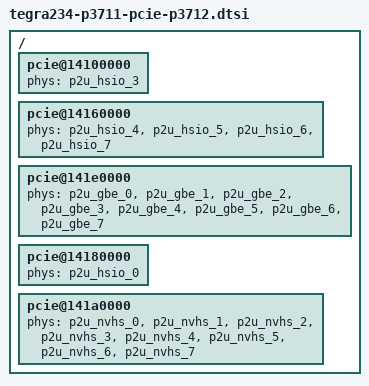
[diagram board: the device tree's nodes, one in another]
/*
 * Copyright (c) 2021, NVIDIA CORPORATION.  All rights reserved.
 *
 * This program is free software; you can redistribute it and/or modify
 * it under the terms of the GNU General Public License as published by
 * the Free Software Foundation; version 2 of the License.
 *
 * This program is distributed in the hope that it will be useful, but WITHOUT
 * ANY WARRANTY; without even the implied warranty of MERCHANTABILITY or
 * FITNESS FOR A PARTICULAR PURPOSE.  See the GNU General Public License for
 * more details.
 */


/ {
	/* C1 - M.2 Key-E */
	pcie@14100000 {
		status = "okay";

		phys = <&p2u_hsio_3>;
		phy-names = "p2u-0";
	};

	/* C4 - M.2 Key-M */
	pcie@14160000 {
		status = "okay";

		phys = <&p2u_hsio_4>, <&p2u_hsio_5>, <&p2u_hsio_6>,
		       <&p2u_hsio_7>;
		phy-names = "p2u-0", "p2u-1", "p2u-2", "p2u-3";
	};

	/* C7 - PCIe switch */
	pcie@141e0000 {
		status = "okay";

		phys = <&p2u_gbe_0>, <&p2u_gbe_1>, <&p2u_gbe_2>, <&p2u_gbe_3>,
		       <&p2u_gbe_4>, <&p2u_gbe_5>, <&p2u_gbe_6>, <&p2u_gbe_7>;
		phy-names = "p2u-0", "p2u-1", "p2u-2", "p2u-3", "p2u-4",
			    "p2u-5", "p2u-6", "p2u-7";
	};

	/* C0 - BMC PCIe UPHY0, Mux with USB recovery */
	pcie@14180000 {
		status = "okay";

		phys = <&p2u_hsio_0>;
		phy-names = "p2u-0";
	};

	/* C5 - P3712 NPM x8 lanes, ODMDATA for C5 x8 is nvhs-uphy-config-0 */
	pcie@141a0000 {
		status = "okay";

		phys = <&p2u_nvhs_0>, <&p2u_nvhs_1>, <&p2u_nvhs_2>,
		       <&p2u_nvhs_3>, <&p2u_nvhs_4>, <&p2u_nvhs_5>,
		       <&p2u_nvhs_6>, <&p2u_nvhs_7>;
		phy-names = "p2u-0", "p2u-1", "p2u-2", "p2u-3", "p2u-4",
			    "p2u-5", "p2u-6", "p2u-7";
	};
};
